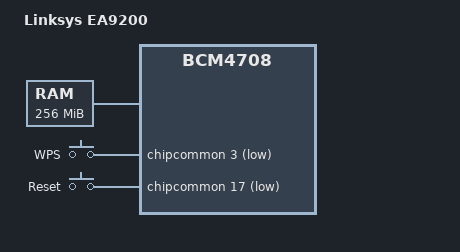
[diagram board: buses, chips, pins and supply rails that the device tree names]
// SPDX-License-Identifier: GPL-2.0-or-later OR MIT
/*
 * Copyright (C) 2017 Rafał Miłecki <rafal@milecki.pl>
 */

/dts-v1/;

#include "bcm4709.dtsi"
#include "bcm5301x-nand-cs0-bch8.dtsi"

/ {
	compatible = "linksys,ea9200", "brcm,bcm4709", "brcm,bcm4708";
	model = "Linksys EA9200";

	chosen {
		bootargs = "console=ttyS0,115200";
	};

	memory {
		reg = <0x00000000 0x08000000
		       0x88000000 0x08000000>;
	};

	gpio-keys {
		compatible = "gpio-keys";
		#address-cells = <1>;
		#size-cells = <0>;

		wps {
			label = "WPS";
			linux,code = <KEY_WPS_BUTTON>;
			gpios = <&chipcommon 3 GPIO_ACTIVE_LOW>;
		};

		restart {
			label = "Reset";
			linux,code = <KEY_RESTART>;
			gpios = <&chipcommon 17 GPIO_ACTIVE_LOW>;
		};
	};
};
